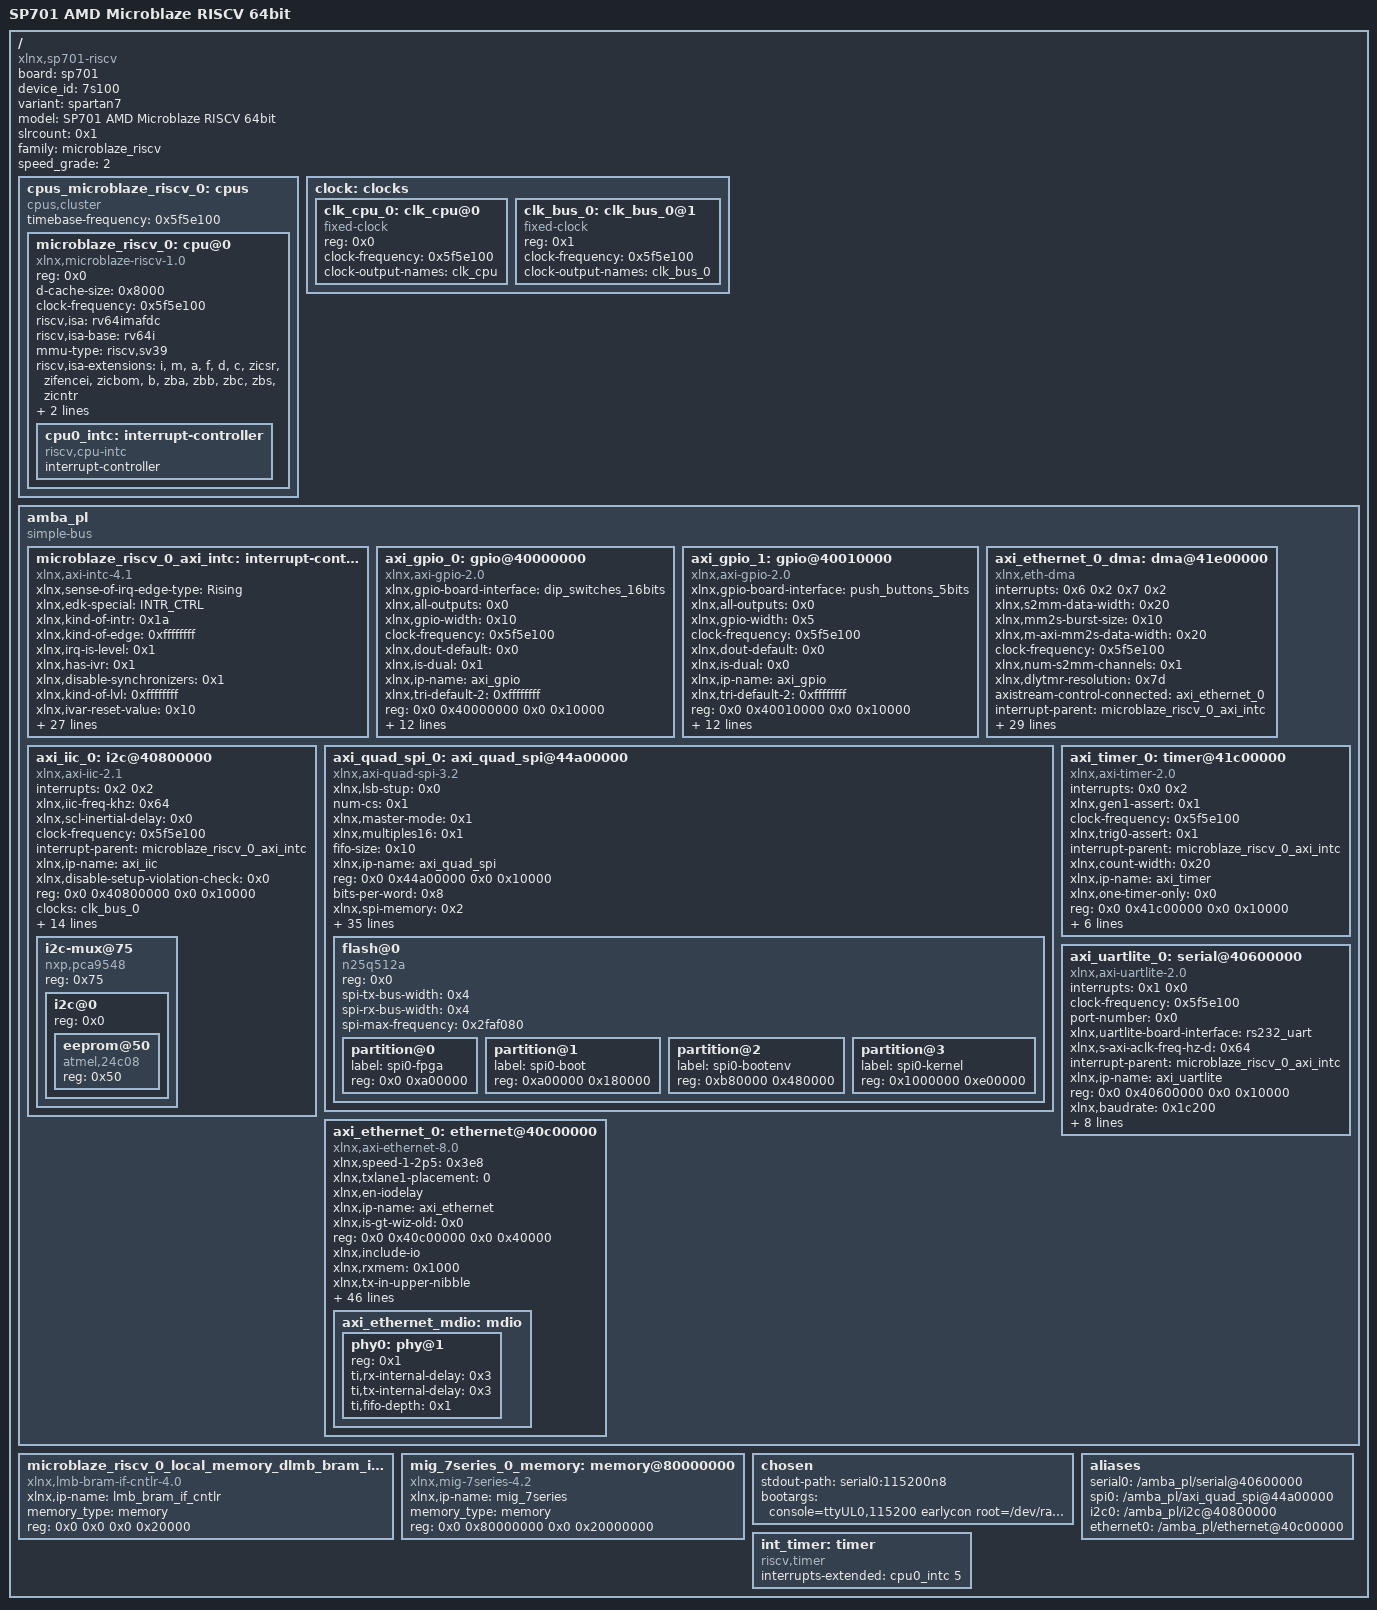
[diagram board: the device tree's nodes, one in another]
/dts-v1/;
/ {
        board = "sp701";
        compatible = "xlnx,sp701-riscv", "qemu,mbv", "amd,mbv";
        device_id = "7s100";
        #address-cells = <0x2>;
        variant = "spartan7";
        model = "SP701 AMD Microblaze RISCV 64bit";
        #size-cells = <0x2>;
        slrcount = <0x1>;
        family = "microblaze_riscv";
        speed_grade = "2";

        cpus_microblaze_riscv_0: cpus {
                phandle = <0x12>;
                #cpu-mask-cells = <0x1>;
                compatible = "cpus,cluster";
                #address-cells = <0x1>;
                bootph-all;
                #size-cells = <0x0>;
                #ranges-address-cells = <0x2>;
                #ranges-size-cells = <0x2>;
                timebase-frequency = <0x5f5e100>;

                microblaze_riscv_0: cpu@0 {
                        phandle = <0x13>;
                        reg = <0x0>;
                        d-cache-size = <0x8000>;
                        bootph-all;
                        clock-frequency = <0x5f5e100>;
                        riscv,isa = "rv64imafdc";
                        compatible = "xlnx,microblaze-riscv-1.0", "amd,mbv64", "riscv", "xlnx,microblaze_riscv";
                        riscv,isa-base = "rv64i";
                        device_type = "cpu";
                        mmu-type = "riscv,sv39";
                        riscv,isa-extensions = "i", "m", "a", "f", "d", "c", "zicsr", "zifencei", "zicbom", "b", "zba", "zbb", "zbc", "zbs", "zicntr";
                        i-cache-size = <0x8000>;
                        clocks = <&clk_cpu_0>;

                        cpu0_intc: interrupt-controller {
                                compatible = "riscv,cpu-intc";
                                #interrupt-cells = <0x1>;
                                interrupt-controller;
                        };
                };
        };

        clock: clocks {
                phandle = <0x14>;
                #address-cells = <0x1>;
                #size-cells = <0x0>;

                clk_cpu_0: clk_cpu@0 {
                        phandle = <0xf>;
                        compatible = "fixed-clock";
                        bootph-all;
                        reg = <0x0>;
                        clock-frequency = <0x5f5e100>;
                        clock-output-names = "clk_cpu";
                        #clock-cells = <0x0>;
                };

                clk_bus_0: clk_bus_0@1 {
                        phandle = <0x10>;
                        compatible = "fixed-clock";
                        bootph-all;
                        reg = <0x1>;
                        clock-frequency = <0x5f5e100>;
                        clock-output-names = "clk_bus_0";
                        #clock-cells = <0x0>;
                };
        };

        amba_pl: amba_pl {
                phandle = <0xd>;
                ranges;
                compatible = "simple-bus";
                #address-cells = <0x2>;
                bootph-all;
                #size-cells = <0x2>;

                microblaze_riscv_0_axi_intc: interrupt-controller@41200000 {
                        phandle = <0x9>;
                        #interrupt-cells = <0x2>;
                        xlnx,sense-of-irq-edge-type = "Rising";
                        xlnx,edk-special = "INTR_CTRL";
                        xlnx,kind-of-intr = <0x1a>;
                        xlnx,kind-of-edge = <0xffffffff>;
                        xlnx,irq-is-level = <0x1>;
                        xlnx,has-ivr = <0x1>;
                        compatible = "xlnx,axi-intc-4.1", "xlnx,xps-intc-1.00.a";
                        xlnx,disable-synchronizers = <0x1>;
                        xlnx,kind-of-lvl = <0xffffffff>;
                        xlnx,ivar-reset-value = <0x10>;
                        xlnx,irq-active = <0x1>;
                        xlnx,en-cascade-mode = <0x0>;
                        xlnx,ip-name = "axi_intc";
                        xlnx,has-ilr = <0x0>;
                        reg = <0x0 0x41200000 0x0 0x10000>;
                        xlnx,addr-width = <0x27>;
                        xlnx,s-axi-aclk-freq-mhz = <0x64>;
                        xlnx,num-sw-intr = <0x0>;
                        xlnx,irq-connection = <0x0>;
                        xlnx,num-intr-inputs = <0x8>;
                        xlnx,has-sie = <0x1>;
                        xlnx,enable-async = <0x0>;
                        xlnx,has-cie = <0x1>;
                        xlnx,num-sync-ff = <0x2>;
                        xlnx,edk-iptype = "PERIPHERAL";
                        xlnx,mb-clk-not-connected = <0x1>;
                        xlnx,has-ipr = <0x1>;
                        xlnx,intc-type = <0x0>;
                        xlnx,sense-of-irq-level-type = "Active_High";
                        xlnx,cascade-master = <0x0>;
                        xlnx,processor-clk-freq-mhz = <0x64>;
                        status = "okay";
                        xlnx,is-fast = <0x1>;
                        xlnx,has-fast = <0x1>;
                        xlnx,ivar-rst-val = <0x10>;
                        interrupt-controller;
                        xlnx,async-intr = <0xffffff38>;
                        interrupts-extended = <&cpu0_intc 9>;
                };

                axi_gpio_0: gpio@40000000 {
                        phandle = <0x4>;
                        xlnx,gpio-board-interface = "dip_switches_16bits";
                        compatible = "xlnx,axi-gpio-2.0", "xlnx,xps-gpio-1.00.a";
                        xlnx,all-outputs = <0x0>;
                        #gpio-cells = <0x2>;
                        xlnx,gpio-width = <0x10>;
                        clock-frequency = <0x5f5e100>;
                        xlnx,dout-default = <0x0>;
                        xlnx,is-dual = <0x1>;
                        xlnx,ip-name = "axi_gpio";
                        xlnx,tri-default-2 = <0xffffffff>;
                        reg = <0x0 0x40000000 0x0 0x10000>;
                        xlnx,all-inputs-2 = <0x0>;
                        clocks = <&clk_bus_0>;
                        xlnx,all-outputs-2 = <0x1>;
                        gpio-controller;
                        device_type = "gpio";
                        xlnx,interrupt-present = <0x0>;
                        xlnx,gpio2-board-interface = "led_8bits";
                        xlnx,edk-iptype = "PERIPHERAL";
                        xlnx,dout-default-2 = <0x0>;
                        status = "okay";
                        xlnx,gpio2-width = <0x8>;
                        clock-names = "s_axi_aclk";
                        xlnx,use-board-flow;
                        xlnx,tri-default = <0xffffffff>;
                        xlnx,all-inputs = <0x1>;
                };

                axi_gpio_1: gpio@40010000 {
                        phandle = <0x5>;
                        xlnx,gpio-board-interface = "push_buttons_5bits";
                        compatible = "xlnx,axi-gpio-2.0", "xlnx,xps-gpio-1.00.a";
                        xlnx,all-outputs = <0x0>;
                        #gpio-cells = <0x2>;
                        xlnx,gpio-width = <0x5>;
                        clock-frequency = <0x5f5e100>;
                        xlnx,dout-default = <0x0>;
                        xlnx,is-dual = <0x0>;
                        xlnx,ip-name = "axi_gpio";
                        xlnx,tri-default-2 = <0xffffffff>;
                        reg = <0x0 0x40010000 0x0 0x10000>;
                        xlnx,all-inputs-2 = <0x0>;
                        clocks = <&clk_bus_0>;
                        xlnx,all-outputs-2 = <0x0>;
                        gpio-controller;
                        device_type = "gpio";
                        xlnx,interrupt-present = <0x0>;
                        xlnx,gpio2-board-interface = "Custom";
                        xlnx,edk-iptype = "PERIPHERAL";
                        xlnx,dout-default-2 = <0x0>;
                        status = "okay";
                        xlnx,gpio2-width = <0x20>;
                        clock-names = "s_axi_aclk";
                        xlnx,use-board-flow;
                        xlnx,tri-default = <0xffffffff>;
                        xlnx,all-inputs = <0x1>;
                };

                axi_ethernet_0_dma: dma@41e00000 {
                        phandle = <0xb>;
                        interrupts = <0x6 0x2 0x7 0x2>;
                        compatible = "xlnx,eth-dma";
                        xlnx,s2mm-data-width = <0x20>;
                        xlnx,mm2s-burst-size = <0x10>;
                        xlnx,m-axi-mm2s-data-width = <0x20>;
                        clock-frequency = <0x5f5e100>;
                        xlnx,num-s2mm-channels = <0x1>;
                        xlnx,dlytmr-resolution = <0x7d>;
                        axistream-control-connected = <&axi_ethernet_0>;
                        interrupt-parent = <&microblaze_riscv_0_axi_intc>;
                        xlnx,sg-length-width = <0x10>;
                        xlnx,prmry-is-aclk-async = <0x0>;
                        xlnx,include-s2mm-sf = <0x1>;
                        #dma-cells = <0x1>;
                        xlnx,ip-name = "axi_dma";
                        xlnx,single-interface = <0x0>;
                        xlnx,sg-include-stscntrl-strm = <0x1>;
                        xlnx,include-s2mm-dre = <0x1>;
                        reg = <0x0 0x41e00000 0x0 0x10000>;
                        xlnx,addr-width = <0x20>;
                        xlnx,include-s2mm = <0x1>;
                        clocks = <&clk_bus_0>;
                        xlnx,s-axis-s2mm-tdata-width = <0x20>;
                        xlnx,micro-dma = <0x0>;
                        xlnx,increase-throughput = <0x0>;
                        xlnx,mm2s-data-width = <0x20>;
                        xlnx,addrwidth = <0x20>;
                        xlnx,sg-use-stsapp-length = <0x1>;
                        xlnx,m-axis-mm2s-tdata-width = <0x20>;
                        xlnx,include-dre;
                        xlnx,edk-iptype = "PERIPHERAL";
                        xlnx,s2mm-burst-size = <0x10>;
                        xlnx,m-axi-s2mm-data-width = <0x20>;
                        xlnx,num-queues = /bits/ 16 <0x0001>;
                        xlnx,num-mm2s-channels = <0x1>;
                        xlnx,enable-multi-channel = <0x0>;
                        status = "okay";
                        xlnx,include-mm2s-sf = <0x1>;
                        clock-names = "s_axi_lite_aclk";
                        axistream-connected = <&axi_ethernet_0>;
                        interrupt-names = "mm2s_introut", "s2mm_introut";
                        xlnx,include-mm2s = <0x1>;
                        xlnx,include-mm2s-dre = <0x1>;
                };

                axi_iic_0: i2c@40800000 {
                        phandle = <0x7>;
                        interrupts = <0x2 0x2>;
                        xlnx,iic-freq-khz = <0x64>;
                        compatible = "xlnx,axi-iic-2.1", "xlnx,xps-iic-2.00.a";
                        xlnx,scl-inertial-delay = <0x0>;
                        clock-frequency = <0x5f5e100>;
                        interrupt-parent = <&microblaze_riscv_0_axi_intc>;
                        xlnx,ip-name = "axi_iic";
                        xlnx,disable-setup-violation-check = <0x0>;
                        reg = <0x0 0x40800000 0x0 0x10000>;
                        clocks = <&clk_bus_0>;
                        xlnx,gpo-width = <0x1>;
                        xlnx,s-axi-aclk-freq-hz = <0x5f5e100>;
                        xlnx,edk-iptype = "PERIPHERAL";
                        xlnx,static-timing-reg-width = <0x0>;
                        xlnx,sda-level = <0x1>;
                        status = "okay";
                        xlnx,use-board-flow;
                        xlnx,ten-bit-adr = <0x0>;
                        xlnx,default-value = <0x0>;
                        interrupt-names = "iic2intc_irpt";
                        xlnx,iic-board-interface = "iic0_main";
                        xlnx,timing-reg-width = <0x20>;
                        xlnx,iic-freq = <0x186a0>;
                        xlnx,smbus-pmbus-host = <0x0>;
                        xlnx,axi-aclk-freq-mhz = <0x64>;
                        xlnx,sda-inertial-delay = <0x0>;
                        #address-cells = <0x1>;
                        #size-cells = <0x0>;

                        i2c-mux@75 {
                                compatible = "nxp,pca9548";
                                #address-cells = <0x1>;
                                #size-cells = <0x0>;
                                reg = <0x75>;

                                i2c@0 {
                                        #address-cells = <0x1>;
                                        #size-cells = <0x0>;
                                        reg = <0x0>;

                                        eeprom@50 {
                                                compatible = "atmel,24c08";
                                                reg = <0x50>;
                                        };
                                };
                        };
                };

                axi_quad_spi_0: axi_quad_spi@44a00000 {
                        phandle = <0xc>;
                        xlnx,lsb-stup = <0x0>;
                        num-cs = <0x1>;
                        xlnx,master-mode = <0x1>;
                        xlnx,multiples16 = <0x1>;
                        fifo-size = <0x10>;
                        xlnx,ip-name = "axi_quad_spi";
                        reg = <0x0 0x44a00000 0x0 0x10000>;
                        bits-per-word = <0x8>;
                        xlnx,spi-memory = <0x2>;
                        xlnx,type-of-axi4-interface = <0x0>;
                        xlnx,use-startup-int = <0x1>;
                        xlnx,slaveonly = <0x0>;
                        xlnx,spi-mode = <0x2>;
                        interrupt-names = "ip2intc_irpt";
                        compatible = "xlnx,axi-quad-spi-3.2", "xlnx,xps-spi-2.00.a";
                        xlnx,byte-level-interrupt-en = <0x0>;
                        xlnx,s-axi4-addr-width = <0x18>;
                        xlnx,sck-ratio = <0x2>;
                        interrupt-parent = <&microblaze_riscv_0_axi_intc>;
                        xlnx,startup-block;
                        xlnx,async-clk = <0x1>;
                        status = "okay";
                        xlnx,sck-ratio1 = <0x1>;
                        xlnx,use-board-flow;
                        xlnx,fifo-included = <0x1>;
                        interrupts = <0x3 0x0>;
                        xlnx,use-startup-ext = <0x0>;
                        xlnx,hasfifos = <0x1>;
                        xlnx,s-axi4-id-width = <0x4>;
                        xlnx,shared-startup = <0x0>;
                        xlnx,new-seq-en = <0x1>;
                        xlnx,qspi-board-interface = "spi_flash";
                        xlnx,edk-iptype = "PERIPHERAL";
                        xlnx,fifo-depth = <0x10>;
                        xlnx,axi-interface = <0x0>;
                        xlnx,num-ss-bits = <0x1>;
                        xlnx,select-xpm = <0x0>;
                        xlnx,xip-mode = <0x0>;
                        bootph-all;
                        xlnx,xip-perf-mode = <0x1>;
                        xlnx,dual-quad-mode = <0x0>;
                        xlnx,num-transfer-bits = <0x8>;
                        xlnx,s-axi4-data-width = <0x20>;
                        xlnx,use-startup = <0x1>;
                        xlnx,spi-mem-addr-bits = <0x18>;
                        xlnx,uc-family = <0x0>;
                        xlnx,sub-family = "spartan7";
                        xlnx,Axi4-address = <0x0>;
                        #address-cells = <0x1>;
                        #size-cells = <0x0>;

                        flash@0 {
                                phandle = <0xe>;
                                compatible = "n25q512a", "jedec,spi-nor";
                                reg = <0x0>;
                                #address-cells = <0x1>;
                                #size-cells = <0x1>;
                                spi-tx-bus-width = <0x4>;
                                spi-rx-bus-width = <0x4>;
                                spi-max-frequency = <0x2faf080>;

                                partition@0 {
                                        label = "spi0-fpga";
                                        reg = <0x0 0xa00000>;
                                };

                                partition@1 {
                                        label = "spi0-boot";
                                        reg = <0xa00000 0x180000>;
                                };

                                partition@2 {
                                        label = "spi0-bootenv";
                                        reg = <0xb80000 0x480000>;
                                };

                                partition@3 {
                                        label = "spi0-kernel";
                                        reg = <0x1000000 0xe00000>;
                                };
                        };
                };

                axi_timer_0: timer@41c00000 {
                        phandle = <0xa>;
                        interrupts = <0x0 0x2>;
                        compatible = "xlnx,axi-timer-2.0", "xlnx,xps-timer-1.00.a";
                        xlnx,gen1-assert = <0x1>;
                        clock-frequency = <0x5f5e100>;
                        xlnx,trig0-assert = <0x1>;
                        interrupt-parent = <&microblaze_riscv_0_axi_intc>;
                        xlnx,count-width = <0x20>;
                        xlnx,ip-name = "axi_timer";
                        xlnx,one-timer-only = <0x0>;
                        reg = <0x0 0x41c00000 0x0 0x10000>;
                        clocks = <&clk_bus_0>;
                        xlnx,gen0-assert = <0x1>;
                        xlnx,mode-64bit = <0x0>;
                        xlnx,edk-iptype = "PERIPHERAL";
                        status = "okay";
                        xlnx,trig1-assert = <0x1>;
                        xlnx,enable-timer2 = <0x1>;
                        interrupt-names = "interrupt";
                };

                axi_uartlite_0: serial@40600000 {
                        phandle = <0x6>;
                        interrupts = <0x1 0x0>;
                        compatible = "xlnx,axi-uartlite-2.0", "xlnx,xps-uartlite-1.00.a";
                        bootph-all;
                        clock-frequency = <0x5f5e100>;
                        port-number = <0x0>;
                        xlnx,uartlite-board-interface = "rs232_uart";
                        xlnx,s-axi-aclk-freq-hz-d = <0x64>;
                        interrupt-parent = <&microblaze_riscv_0_axi_intc>;
                        xlnx,ip-name = "axi_uartlite";
                        reg = <0x0 0x40600000 0x0 0x10000>;
                        xlnx,baudrate = <0x1c200>;
                        clocks = <&clk_bus_0>;
                        current-speed = <0x1c200>;
                        device_type = "serial";
                        xlnx,use-parity = <0x0>;
                        xlnx,edk-iptype = "PERIPHERAL";
                        xlnx,odd-parity = <0x0>;
                        status = "okay";
                        xlnx,use-board-flow;
                        interrupt-names = "interrupt";
                        xlnx,data-bits = <0x8>;
                        xlnx,parity = "No_Parity";
                };

                axi_ethernet_0: ethernet@40c00000 {
                        phandle = <0x8>;
                        xlnx,speed-1-2p5 = <0x3e8>;
                        xlnx,txlane1-placement = "0";
                        xlnx,en-iodelay;
                        xlnx,ip-name = "axi_ethernet";
                        xlnx,is-gt-wiz-old = <0x0>;
                        reg = <0x0 0x40c00000 0x0 0x40000>;
                        xlnx,include-io;
                        xlnx,rxmem = <0x1000>;
                        xlnx,tx-in-upper-nibble;
                        xlnx,axisclkrate = <0x0>;
                        xlnx,txmem = "0";
                        xlnx,mdio-board-interface = "0";
                        xlnx,phyaddr = <0x1>;
                        xlnx,supportlevel = <0x0>;
                        local-mac-address = [00 0A 23 00 00 00];
                        xlnx,diffclk-board-interface = "0";
                        xlnx,frame-filter;
                        axistream-connected = <&axi_ethernet_0_dma>;
                        interrupt-names = "interrupt", "mac_irq", "mm2s_introut", "s2mm_introut";
                        xlnx,phyrst-board-interface-dummy-port = "0";
                        compatible = "xlnx,axi-ethernet-8.0", "xlnx,axi-ethernet-1.00.a", "xlnx,axi-ethernet-1.00.a";
                        xlnx,gt-type = "0";
                        xlnx,drpclkrate = <0x0>;
                        clock-frequency;
                        axistream-control-connected = <&axi_ethernet_0_dma>;
                        interrupt-parent = <&microblaze_riscv_0_axi_intc>;
                        xlnx,versal-gt-board-flow = <0x0>;
                        device_type = "network";
                        xlnx,num-queues = /bits/ 16 <0x0001>;
                        xlnx,channel-ids = <0x1>;
                        max-speed = <0x3e8>;
                        status = "okay";
                        xlnx,timer-format = <0x0>;
                        xlnx,use-board-flow;
                        xlnx,statistics-width = "0";
                        interrupts = <0x5 0x2 0x4 0x0>;
                        xlnx,gtrefclksrc = "0";
                        xlnx,rxcsum = <0x0>;
                        xlnx,statistics-counters;
                        xlnx,include-dre;
                        xlnx,edk-iptype = "0";
                        xlnx,gtrefclkrate = <0x0>;
                        xlnx,lvdsclkrate = <0x0>;
                        xlnx,number-of-table-entries = <0x0>;
                        xlnx,rxlane0-placement = "0";
                        xlnx,timer-clk-period = <0x0>;
                        xlnx,ethernet-board-interface = "0";
                        xlnx,txlane0-placement = "0";
                        xlnx,gtlocation = "0";
                        phy-mode = "rgmii";
                        xlnx,gt-settings = <0x0>;
                        xlnx,clockselection = "0";
                        xlnx,processor-mode;
                        xlnx,txcsum = <0x0>;
                        xlnx,phyrst-board-interface = "0";
                        xlnx,axiliteclkrate = <0x0>;
                        xlnx,rxlane1-placement = "0";
                        phy-handle = <0x11>;

                        axi_ethernet_mdio: mdio {
                                phandle = <0x16>;
                                #address-cells = <0x1>;
                                #size-cells = <0x0>;

                                phy0: phy@1 {
                                        phandle = <0x11>;
                                        device_type = "ethernet-phy";
                                        reg = <0x1>;
                                        ti,rx-internal-delay = <0x3>;
                                        ti,tx-internal-delay = <0x3>;
                                        ti,fifo-depth = <0x1>;
                                };
                        };
                };
        };

        microblaze_riscv_0_local_memory_dlmb_bram_if_cntlr_memory: sram@0 {
                phandle = <0x1>;
                ranges = <0x0 0x0 0x0 0x0 0x20000>;
                compatible = "xlnx,lmb-bram-if-cntlr-4.0", "mmio-sram";
                #address-cells = <0x2>;
                xlnx,ip-name = "lmb_bram_if_cntlr";
                #size-cells = <0x2>;
                memory_type = "memory";
                reg = <0x0 0x0 0x0 0x20000>;
        };

        mig_7series_0_memory: memory@80000000 {
                phandle = <0x3>;
                compatible = "xlnx,mig-7series-4.2";
                xlnx,ip-name = "mig_7series";
                device_type = "memory";
                memory_type = "memory";
                reg = <0x0 0x80000000 0x0 0x20000000>;
        };

        chosen {
                stdout-path = "serial0:115200n8";
                bootargs = "console=ttyUL0,115200 earlycon root=/dev/ram0 rw";
        };

        aliases {
                serial0 = "/amba_pl/serial@40600000";
                spi0 = "/amba_pl/axi_quad_spi@44a00000";
                i2c0 = "/amba_pl/i2c@40800000";
                ethernet0 = "/amba_pl/ethernet@40c00000";
        };

        __symbols__ {
                cpus_microblaze_riscv_0 = "/cpus_microblaze_riscv@0";
                microblaze_riscv_0 = "/cpus_microblaze_riscv@0/cpu@0";
                clock = "/clocks";
                clk_cpu_0 = "/clocks/clk_cpu@0";
                clk_bus_0 = "/clocks/clk_bus_0@1";
                amba_pl = "/amba_pl";
                microblaze_riscv_0_axi_intc = "/amba_pl/interrupt-controller@41200000";
                axi_gpio_0 = "/amba_pl/gpio@40000000";
                axi_gpio_1 = "/amba_pl/gpio@40010000";
                axi_ethernet_0_dma = "/amba_pl/dma@41e00000";
                axi_iic_0 = "/amba_pl/i2c@40800000";
                axi_quad_spi_0 = "/amba_pl/axi_quad_spi@44a00000";
                axi_timer_0 = "/amba_pl/timer@41c00000";
                axi_uartlite_0 = "/amba_pl/serial@40600000";
                axi_ethernet_0 = "/amba_pl/ethernet@40c00000";
                axi_ethernet_mdio = "/amba_pl/ethernet@40c00000/mdio";
                phy0 = "/amba_pl/ethernet@40c00000/mdio/phy@1";
                microblaze_riscv_0_local_memory_dlmb_bram_if_cntlr_memory = "/memory@0";
                mig_7series_0_memory = "/memory@80000000";
        };

        int_timer: timer {
                compatible = "riscv,timer";
                bootph-all;
                interrupts-extended = <&cpu0_intc 5>;
        };
};
